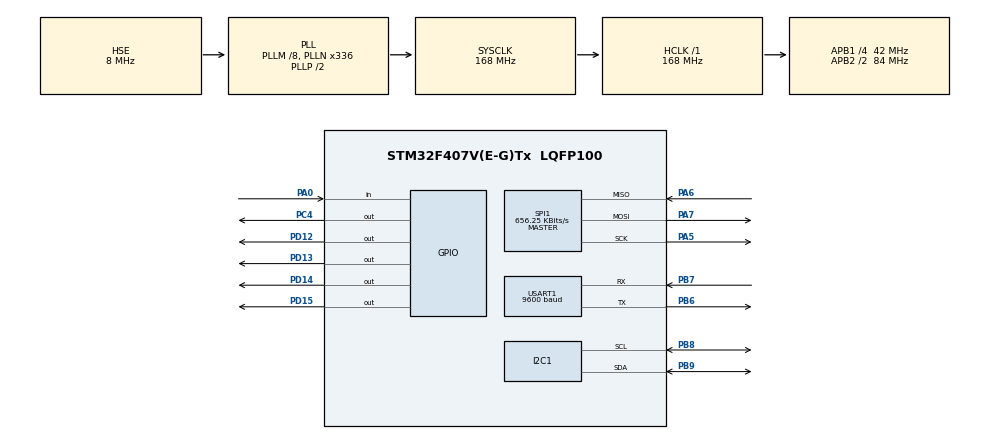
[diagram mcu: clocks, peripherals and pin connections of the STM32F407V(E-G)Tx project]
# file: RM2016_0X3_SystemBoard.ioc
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Mcu.Family=STM32F4
Mcu.Name=STM32F407V(E-G)Tx
Mcu.Package=LQFP100
NVIC.PriorityGroup=NVIC_PRIORITYGROUP_2
NVIC.SPI1_IRQn=true\:2\:0\:true
NVIC.TIM2_IRQn=true\:2\:0\:true
NVIC.USART1_IRQn=true\:2\:0\:true
PA0-WKUP.GPIO_PuPd=GPIO_NOPULL
PA0-WKUP.Signal=GPIO_Input
PA5.GPIO_PuPd=GPIO_PULLUP
PA5.Mode=Full_Duplex_Master
PA5.Signal=SPI1_SCK
PA6.GPIO_PuPd=GPIO_PULLUP
PA6.Mode=Full_Duplex_Master
PA6.Signal=SPI1_MISO
PA7.GPIO_PuPd=GPIO_PULLUP
PA7.Mode=Full_Duplex_Master
PA7.Signal=SPI1_MOSI
PB6.Mode=Asynchronous
PB6.Signal=USART1_TX
PB7.Mode=Asynchronous
PB7.Signal=USART1_RX
PB8.Mode=I2C
PB8.Signal=I2C1_SCL
PB9.Mode=I2C
PB9.Signal=I2C1_SDA
PC4.Signal=GPIO_Output
PD12.GPIO_PuPd=GPIO_PULLUP
PD12.GPIO_Speed=GPIO_SPEED_MEDIUM
PD12.Signal=GPIO_Output
PD13.Signal=GPIO_Output
PD14.Signal=GPIO_Output
PD15.Signal=GPIO_Output
PH0-OSC_IN.Mode=HSE-External-Clock-Source
PH0-OSC_IN.Signal=RCC_OSC_IN
PH1-OSC_OUT.Mode=HSE-External-Clock-Source
PH1-OSC_OUT.Signal=RCC_OSC_OUT
ProjectManager.TargetToolchain=MDK-ARM V5
RCC.48MHZClocksFreq_Value=84000000
RCC.AHBFreq_Value=168000000
RCC.APB1CLKDivider=RCC_HCLK_DIV4
RCC.APB1Freq_Value=42000000
RCC.APB1TimFreq_Value=84000000
RCC.APB2CLKDivider=RCC_HCLK_DIV2
RCC.APB2Freq_Value=84000000
RCC.APB2TimFreq_Value=168000000
RCC.CortexFreq_Value=168000000
RCC.HCLKFreq_Value=168000000
RCC.HSE_VALUE=8000000
RCC.HSI_VALUE=16000000
RCC.LSE_VALUE=32768
RCC.PLLM=8
RCC.PLLN=336
RCC.PLLSourceVirtual=RCC_PLLSOURCE_HSE
RCC.SYSCLKFreq_VALUE=168000000
RCC.SYSCLKSource=RCC_SYSCLKSOURCE_PLLCLK
RCC.VCOOutputFreq_Value=336000000
SPI1.BaudRatePrescaler=SPI_BAUDRATEPRESCALER_128
SPI1.CLKPhase=SPI_PHASE_2EDGE
SPI1.CLKPolarity=SPI_POLARITY_HIGH
SPI1.CalculateBaudRate=656.25 KBits/s
SPI1.Mode=SPI_MODE_MASTER
TIM2.Period=1
TIM2.Prescaler=1
USART1.BaudRate=9600
VP_TIM2_VS_ClockSourceINT.Mode=Internal
board=RM2016_0X3_SystemBoard

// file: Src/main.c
/**
  ******************************************************************************
  * File Name          : main.c
  * Description        : Main program body
  ******************************************************************************
  *
  * COPYRIGHT(c) 2016 STMicroelectronics
  *
  * Redistribution and use in source and binary forms, with or without modification,
  * are permitted provided that the following conditions are met:
  *   1. Redistributions of source code must retain the above copyright notice,
  *      this list of conditions and the following disclaimer.
  *   2. Redistributions in binary form must reproduce the above copyright notice,
  *      this list of conditions and the following disclaimer in the documentation
  *      and/or other materials provided with the distribution.
  *   3. Neither the name of STMicroelectronics nor the names of its contributors
  *      may be used to endorse or promote products derived from this software
  *      without specific prior written permission.
  *
  * THIS SOFTWARE IS PROVIDED BY THE COPYRIGHT HOLDERS AND CONTRIBUTORS "AS IS"
  * AND ANY EXPRESS OR IMPLIED WARRANTIES, INCLUDING, BUT NOT LIMITED TO, THE
  * IMPLIED WARRANTIES OF MERCHANTABILITY AND FITNESS FOR A PARTICULAR PURPOSE ARE
  * DISCLAIMED. IN NO EVENT SHALL THE COPYRIGHT HOLDER OR CONTRIBUTORS BE LIABLE
  * FOR ANY DIRECT, INDIRECT, INCIDENTAL, SPECIAL, EXEMPLARY, OR CONSEQUENTIAL
  * DAMAGES (INCLUDING, BUT NOT LIMITED TO, PROCUREMENT OF SUBSTITUTE GOODS OR
  * SERVICES; LOSS OF USE, DATA, OR PROFITS; OR BUSINESS INTERRUPTION) HOWEVER
  * CAUSED AND ON ANY THEORY OF LIABILITY, WHETHER IN CONTRACT, STRICT LIABILITY,
  * OR TORT (INCLUDING NEGLIGENCE OR OTHERWISE) ARISING IN ANY WAY OUT OF THE USE
  * OF THIS SOFTWARE, EVEN IF ADVISED OF THE POSSIBILITY OF SUCH DAMAGE.
  *
  ******************************************************************************
  */
#include "stm32f4xx_hal.h"
#include "i2c.h"
#include "spi.h"
#include "tim.h"
#include "usart.h"
#include "gpio.h"

/* USER CODE BEGIN Includes */
#include "system.h"
#include "stm32f4_discovery.h"
#include "mpu9255.h"
/* USER CODE END Includes */

/* USER CODE BEGIN PV */
/* Private variables ---------------------------------------------------------*/
//uint8_t dataSend[14],dataReceive[10],count=0xAA;
__IO ITStatus UartReady = RESET;
/* USER CODE END PV */

void SystemClock_Config(void);

/* USER CODE BEGIN PFP */
/* Private function prototypes -----------------------------------------------*/

/* USER CODE END PFP */

int main(void)
{

  /* MCU Configuration----------------------------------------------------------*/

  /* Reset of all peripherals, Initializes the Flash interface and the Systick. */
  HAL_Init();

  /* Configure the system clock */
  SystemClock_Config();

  /* Initialize all configured peripherals */
  MX_GPIO_Init();
  MX_I2C1_Init();
  MX_SPI1_Init();
  MX_TIM2_Init();
  MX_USART1_UART_Init();

  /* USER CODE BEGIN 2 */
	while(!MPU9255_Init());
	LED5_High;
	if(HAL_TIM_Base_Start_IT(&htim2)==HAL_OK)LED6_High;
  /* USER CODE END 2 */

  /* Infinite loop */
  while (1)
  {

  /* USER CODE BEGIN 3 */
//		if(MPU9255_Read_Reg(WHO_AM_I)==0x73)
//			LED3_Toggle;
//		Delay(0xFFFFF);
//		MPU9255_ReadValue(dataSend);
//		HAL_UART_Transmit(&huart1, dataSend, 14, 0xFFFF);
//		HAL_UART_Transmit(&huart1, &count, 1, 0xFFFF);
//		Delay(0xFFFFF);
//		HAL_SPI_Transmit(&hspi1, dataSend, 1, 0xFFFF);

//		SPI_MPU9255_CS_H;
//		Delay(0xFFFF);
//		SPI_MPU9255_CS_L;
//		Delay(0xFFFF);
//		HAL_UART_Transmit(&huart1,dataSend,10,0xFFFF);
//		Delay(0xFFFFF);
//		HAL_UART_RxCpltCallback(&huart1);
  }
  /* USER CODE END 3 */

}

/** System Clock Configuration
*/
void SystemClock_Config(void)
{

  RCC_OscInitTypeDef RCC_OscInitStruct;
  RCC_ClkInitTypeDef RCC_ClkInitStruct;

  __PWR_CLK_ENABLE();

  __HAL_PWR_VOLTAGESCALING_CONFIG(PWR_REGULATOR_VOLTAGE_SCALE1);

  RCC_OscInitStruct.OscillatorType = RCC_OSCILLATORTYPE_HSE;
  RCC_OscInitStruct.HSEState = RCC_HSE_BYPASS;
  RCC_OscInitStruct.PLL.PLLState = RCC_PLL_ON;
  RCC_OscInitStruct.PLL.PLLSource = RCC_PLLSOURCE_HSE;
  RCC_OscInitStruct.PLL.PLLM = 8;
  RCC_OscInitStruct.PLL.PLLN = 336;
  RCC_OscInitStruct.PLL.PLLP = RCC_PLLP_DIV2;
  RCC_OscInitStruct.PLL.PLLQ = 4;
  HAL_RCC_OscConfig(&RCC_OscInitStruct);

  RCC_ClkInitStruct.ClockType = RCC_CLOCKTYPE_SYSCLK|RCC_CLOCKTYPE_PCLK1
                              |RCC_CLOCKTYPE_PCLK2;
  RCC_ClkInitStruct.SYSCLKSource = RCC_SYSCLKSOURCE_PLLCLK;
  RCC_ClkInitStruct.AHBCLKDivider = RCC_SYSCLK_DIV1;
  RCC_ClkInitStruct.APB1CLKDivider = RCC_HCLK_DIV4;
  RCC_ClkInitStruct.APB2CLKDivider = RCC_HCLK_DIV2;
  HAL_RCC_ClockConfig(&RCC_ClkInitStruct, FLASH_LATENCY_5);

  HAL_SYSTICK_Config(HAL_RCC_GetHCLKFreq()/1000);

  HAL_SYSTICK_CLKSourceConfig(SYSTICK_CLKSOURCE_HCLK);

  /* SysTick_IRQn interrupt configuration */
  HAL_NVIC_SetPriority(SysTick_IRQn, 0, 0);
}

/* USER CODE BEGIN 4 */
void HAL_UART_RxCpltCallback(UART_HandleTypeDef *UartHandle)
{
//	HAL_UART_Transmit(UartHandle,dataReceive,1,0xFFFF);
//	if(HAL_UART_Receive_IT(&huart1, dataReceive, 1)==HAL_OK)LED3_High;
}

void HAL_SYSTICK_Callback(void)
{
//	if(MPU9255_Init())
//		{
//			MPU9255_ReadValue(dataSend);
//			HAL_UART_Transmit(&huart1, dataSend, 2, 0xFFFF);
//			HAL_UART_Transmit(&huart1, &count, 1, 0xFFFF);
//		}
	//系统时钟中断 10ms进一次
}

/* USER CODE END 4 */

/************************ (C) COPYRIGHT STMicroelectronics *****END OF FILE****/
